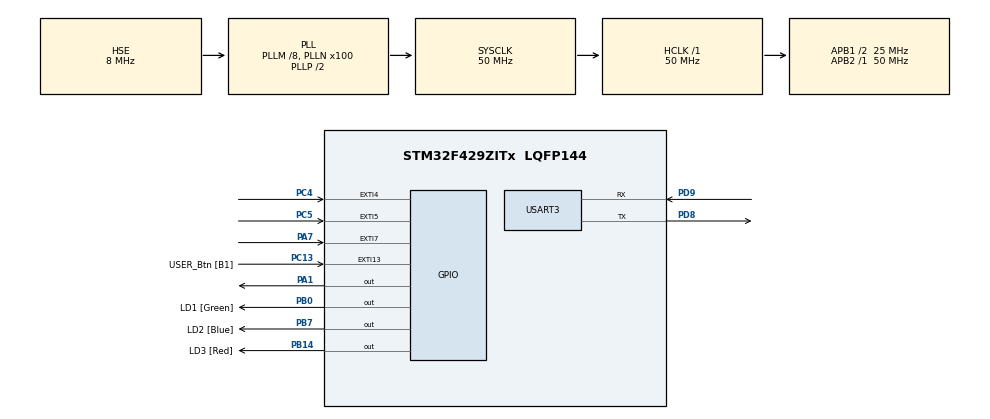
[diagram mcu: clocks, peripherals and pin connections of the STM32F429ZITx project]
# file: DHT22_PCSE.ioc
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Mcu.Family=STM32F4
Mcu.Name=STM32F429ZITx
Mcu.Package=LQFP144
NVIC.PriorityGroup=NVIC_PRIORITYGROUP_4
PA1.Signal=GPIO_Output
PA14.GPIO_Label=TCK
PA14.Signal=SYS_JTCK-SWCLK
PA7.Signal=GPXTI7
PB0.GPIO_Label=LD1 [Green]
PB0.Signal=GPIO_Output
PB14.GPIO_Label=LD3 [Red]
PB14.Signal=GPIO_Output
PB7.GPIO_Label=LD2 [Blue]
PB7.Signal=GPIO_Output
PC13.GPIO_Label=USER_Btn [B1]
PC13.Signal=GPXTI13
PC14/OSC32_IN.Signal=RCC_OSC32_IN
PC15/OSC32_OUT.Signal=RCC_OSC32_OUT
PC4.Signal=GPXTI4
PC5.Signal=GPXTI5
PD8.Mode=Asynchronous
PD8.Signal=USART3_TX
PD9.Mode=Asynchronous
PD9.Signal=USART3_RX
PG11.GPIO_Label=RMII_TX_EN [LAN8742A-CZ-TR_TXEN]
PG11.Signal=ETH_TX_EN
PG13.GPIO_Label=RMII_TXD0 [LAN8742A-CZ-TR_TXD0]
PG13.Signal=ETH_TXD0
PH0/OSC_IN.GPIO_Label=MCO [STM32F103CBT6_PA8]
PH0/OSC_IN.Mode=HSE-External-Oscillator
PH0/OSC_IN.Signal=RCC_OSC_IN
PH1/OSC_OUT.Mode=HSE-External-Oscillator
PH1/OSC_OUT.Signal=RCC_OSC_OUT
ProjectManager.HeapSize=0x200
ProjectManager.StackSize=0x400
ProjectManager.TargetToolchain=STM32CubeIDE
RCC.48MHZClocksFreq_Value=25000000
RCC.AHBFreq_Value=50000000
RCC.APB1CLKDivider=RCC_HCLK_DIV2
RCC.APB1Freq_Value=25000000
RCC.APB1TimFreq_Value=50000000
RCC.APB2Freq_Value=50000000
RCC.APB2TimFreq_Value=50000000
RCC.CortexFreq_Value=50000000
RCC.HCLKFreq_Value=50000000
RCC.HSE_VALUE=8000000
RCC.HSI_VALUE=16000000
RCC.LSE_VALUE=32768
RCC.PLLM=8
RCC.PLLMUL=RCC_PLL_MUL9
RCC.PLLN=100
RCC.PLLSourceVirtual=RCC_PLLSOURCE_HSE
RCC.PRESCALERUSB=RCC_USBCLKSOURCE_PLL_DIV1_5
RCC.SYSCLKFreq_VALUE=50000000
RCC.SYSCLKSource=RCC_SYSCLKSOURCE_PLLCLK
RCC.SYSCLKSourceVirtual=RCC_SYSCLKSOURCE_PLLCLK
RCC.USBFreq_Value=48000000
RCC.VCOOutputFreq_Value=100000000
USART3.VirtualMode=VM_ASYNC
VP_TIM6_VS_ClockSourceINT.Mode=Enable_Timer
board=NUCLEO-F429ZI

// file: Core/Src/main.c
/* USER CODE BEGIN Header */
/**
 ******************************************************************************
 * @file           : main.c
 * @brief          : Main program body
 ******************************************************************************
 * @attention
 *
 * Copyright (c) 2022 STMicroelectronics.
 * All rights reserved.
 *
 * This software is licensed under terms that can be found in the LICENSE file
 * in the root directory of this software component.
 * If no LICENSE file comes with this software, it is provided AS-IS.
 *
 ******************************************************************************
 */
/* USER CODE END Header */
#include "main.h"
#include "stdio.h"
#include "string.h"
#include "DHT22.h"

TIM_HandleTypeDef htim6;

UART_HandleTypeDef huart3;

/* USER CODE BEGIN PV */
float temperatura;
float humedad;

#define DHT_PIN GPIO_PIN_3  //Para definir que pin se utilizará en el driver

/* USER CODE END PV */

void SystemClock_Config(void);
static void MX_GPIO_Init(void);
static void MX_TIM6_Init(void);
static void MX_USART3_UART_Init(void);

int main(void)
{

	/* MCU Configuration--------------------------------------------------------*/

	/* Reset of all peripherals, Initializes the Flash interface and the Systick. */
	HAL_Init();

	/* Configure the system clock */
	SystemClock_Config();

	/* Initialize all configured peripherals */
	MX_GPIO_Init();
	MX_TIM6_Init();
	MX_USART3_UART_Init();

	/* USER CODE BEGIN 2 */
	HAL_TIM_Base_Start(&htim6);

	char dato[] = "inicia";
	HAL_UART_Transmit(&huart3, dato, sizeof(dato), 50);
	/* USER CODE END 2 */

	/* Infinite loop */
	/* USER CODE BEGIN WHILE */
	while (1)
	{

		char msj[]="\n\r";
		HAL_UART_Transmit(&huart3, msj, sizeof(msj), 50);

		DHT_start();

		Toma_Valores(DHT_PIN);

		temperatura = Recive_Temperatura();
		humedad = Recive_Humedad();

		HAL_UART_Transmit(&huart3, (uint8_t *)"Temp: ", 10, 50);
		sprintf(msj, "%2f", temperatura);
		HAL_UART_Transmit(&huart3, msj, sizeof(msj), 50);
		HAL_UART_Transmit(&huart3, (uint8_t *)"\n\r", 2, 50);

		HAL_UART_Transmit(&huart3, (uint8_t *)"Hum: ", 10, 50);
		sprintf(msj, "%2f", humedad);
		HAL_UART_Transmit(&huart3, msj, sizeof(msj), 50);

		HAL_Delay(3000);

		/* USER CODE END WHILE */
	}
}

void SystemClock_Config(void)
{
	RCC_OscInitTypeDef RCC_OscInitStruct = {0};
	RCC_ClkInitTypeDef RCC_ClkInitStruct = {0};

	/** Configure the main internal regulator output voltage
	 */
	__HAL_RCC_PWR_CLK_ENABLE();
	__HAL_PWR_VOLTAGESCALING_CONFIG(PWR_REGULATOR_VOLTAGE_SCALE3);

	/** Initializes the RCC Oscillators according to the specified parameters
	 * in the RCC_OscInitTypeDef structure.
	 */
	RCC_OscInitStruct.OscillatorType = RCC_OSCILLATORTYPE_HSE;
	RCC_OscInitStruct.HSEState = RCC_HSE_ON;
	RCC_OscInitStruct.PLL.PLLState = RCC_PLL_ON;
	RCC_OscInitStruct.PLL.PLLSource = RCC_PLLSOURCE_HSE;
	RCC_OscInitStruct.PLL.PLLM = 8;
	RCC_OscInitStruct.PLL.PLLN = 100;
	RCC_OscInitStruct.PLL.PLLP = RCC_PLLP_DIV2;
	RCC_OscInitStruct.PLL.PLLQ = 4;
	if (HAL_RCC_OscConfig(&RCC_OscInitStruct) != HAL_OK)
	{
		Error_Handler();
	}

	/** Initializes the CPU, AHB and APB buses clocks
	 */
	RCC_ClkInitStruct.ClockType = RCC_CLOCKTYPE_HCLK|RCC_CLOCKTYPE_SYSCLK
			|RCC_CLOCKTYPE_PCLK1|RCC_CLOCKTYPE_PCLK2;
	RCC_ClkInitStruct.SYSCLKSource = RCC_SYSCLKSOURCE_PLLCLK;
	RCC_ClkInitStruct.AHBCLKDivider = RCC_SYSCLK_DIV1;
	RCC_ClkInitStruct.APB1CLKDivider = RCC_HCLK_DIV2;
	RCC_ClkInitStruct.APB2CLKDivider = RCC_HCLK_DIV1;

	if (HAL_RCC_ClockConfig(&RCC_ClkInitStruct, FLASH_LATENCY_1) != HAL_OK)
	{
		Error_Handler();
	}
}

static void MX_TIM6_Init(void)
{

	TIM_MasterConfigTypeDef sMasterConfig = {0};

	htim6.Instance = TIM6;
	htim6.Init.Prescaler = 50-1;
	htim6.Init.CounterMode = TIM_COUNTERMODE_UP;
	htim6.Init.Period = 0xffff-1;
	htim6.Init.AutoReloadPreload = TIM_AUTORELOAD_PRELOAD_DISABLE;
	if (HAL_TIM_Base_Init(&htim6) != HAL_OK)
	{
		Error_Handler();
	}
	sMasterConfig.MasterOutputTrigger = TIM_TRGO_RESET;
	sMasterConfig.MasterSlaveMode = TIM_MASTERSLAVEMODE_DISABLE;
	if (HAL_TIMEx_MasterConfigSynchronization(&htim6, &sMasterConfig) != HAL_OK)
	{
		Error_Handler();
	}

}

static void MX_USART3_UART_Init(void)
{

	huart3.Instance = USART3;
	huart3.Init.BaudRate = 9600;
	huart3.Init.WordLength = UART_WORDLENGTH_8B;
	huart3.Init.StopBits = UART_STOPBITS_1;
	huart3.Init.Parity = UART_PARITY_NONE;
	huart3.Init.Mode = UART_MODE_TX_RX;
	huart3.Init.HwFlowCtl = UART_HWCONTROL_NONE;
	huart3.Init.OverSampling = UART_OVERSAMPLING_16;
	if (HAL_UART_Init(&huart3) != HAL_OK)
	{
		Error_Handler();
	}

}

static void MX_GPIO_Init(void)
{
	GPIO_InitTypeDef GPIO_InitStruct = {0};

	/* GPIO Ports Clock Enable */
	__HAL_RCC_GPIOC_CLK_ENABLE();
	__HAL_RCC_GPIOH_CLK_ENABLE();
	__HAL_RCC_GPIOA_CLK_ENABLE();
	__HAL_RCC_GPIOB_CLK_ENABLE();
	__HAL_RCC_GPIOD_CLK_ENABLE();
	__HAL_RCC_GPIOG_CLK_ENABLE();

	/*Configure GPIO pin Output Level */
	HAL_GPIO_WritePin(GPIOA, GPIO_PIN_3, GPIO_PIN_RESET);

	/*Configure GPIO pin Output Level */
	HAL_GPIO_WritePin(GPIOB, LD1_Pin|LD3_Pin|LD2_Pin, GPIO_PIN_RESET);

	/*Configure GPIO pins : USER_Btn_Pin PC4 PC5 */
	GPIO_InitStruct.Pin = USER_Btn_Pin|GPIO_PIN_4|GPIO_PIN_5;
	GPIO_InitStruct.Mode = GPIO_MODE_IT_RISING;
	GPIO_InitStruct.Pull = GPIO_NOPULL;
	HAL_GPIO_Init(GPIOC, &GPIO_InitStruct);

	/*Configure GPIO pin : PA1 */
	GPIO_InitStruct.Pin = GPIO_PIN_3;
	GPIO_InitStruct.Mode = GPIO_MODE_OUTPUT_PP;
	GPIO_InitStruct.Pull = GPIO_NOPULL;
	GPIO_InitStruct.Speed = GPIO_SPEED_FREQ_LOW;
	HAL_GPIO_Init(GPIOA, &GPIO_InitStruct);

	/*Configure GPIO pin : PA7 */
	GPIO_InitStruct.Pin = GPIO_PIN_7;
	GPIO_InitStruct.Mode = GPIO_MODE_IT_RISING;
	GPIO_InitStruct.Pull = GPIO_NOPULL;
	HAL_GPIO_Init(GPIOA, &GPIO_InitStruct);

	/*Configure GPIO pins : LD1_Pin LD3_Pin LD2_Pin */
	GPIO_InitStruct.Pin = LD1_Pin|LD3_Pin|LD2_Pin;
	GPIO_InitStruct.Mode = GPIO_MODE_OUTPUT_PP;
	GPIO_InitStruct.Pull = GPIO_NOPULL;
	GPIO_InitStruct.Speed = GPIO_SPEED_FREQ_LOW;
	HAL_GPIO_Init(GPIOB, &GPIO_InitStruct);

	/*Configure GPIO pins : RMII_TX_EN_Pin RMII_TXD0_Pin */
	GPIO_InitStruct.Pin = RMII_TX_EN_Pin|RMII_TXD0_Pin;
	GPIO_InitStruct.Mode = GPIO_MODE_AF_PP;
	GPIO_InitStruct.Pull = GPIO_NOPULL;
	GPIO_InitStruct.Speed = GPIO_SPEED_FREQ_VERY_HIGH;
	GPIO_InitStruct.Alternate = GPIO_AF11_ETH;
	HAL_GPIO_Init(GPIOG, &GPIO_InitStruct);

}

void Error_Handler(void)
{
	__disable_irq();
	while (1)
	{
	}
}
